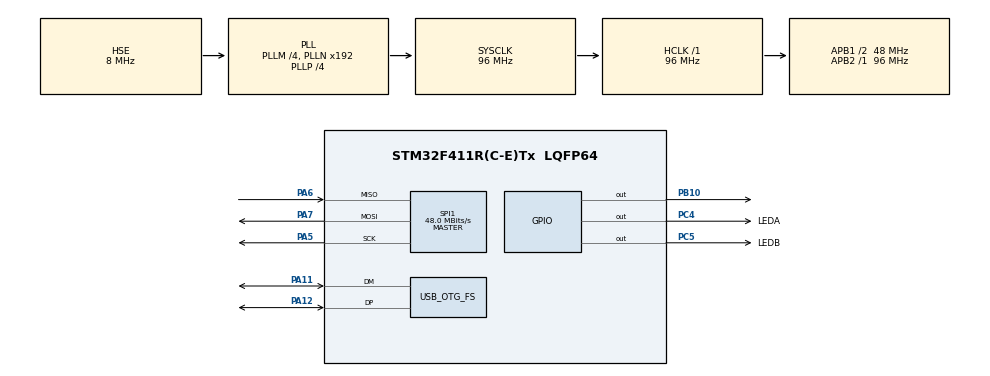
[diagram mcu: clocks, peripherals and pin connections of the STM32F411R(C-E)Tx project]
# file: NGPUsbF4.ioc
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Mcu.Family=STM32F4
Mcu.Name=STM32F411R(C-E)Tx
Mcu.Package=LQFP64
NVIC.OTG_FS_IRQn=true\:0\:0\:false\:false\:true
NVIC.PriorityGroup=NVIC_PRIORITYGROUP_4
PA11.Mode=Device_Only
PA11.Signal=USB_OTG_FS_DM
PA12.Mode=Device_Only
PA12.Signal=USB_OTG_FS_DP
PA5.Mode=Full_Duplex_Master
PA5.Signal=SPI1_SCK
PA6.Mode=Full_Duplex_Master
PA6.Signal=SPI1_MISO
PA7.Mode=Full_Duplex_Master
PA7.Signal=SPI1_MOSI
PB10.GPIO_ModeDefaultOutputPP=GPIO_MODE_OUTPUT_PP
PB10.GPIO_PuPd=GPIO_NOPULL
PB10.GPIO_Speed=GPIO_SPEED_FREQ_LOW
PB10.PinState=GPIO_PIN_RESET
PB10.Signal=GPIO_Output
PC14-OSC32_IN.Mode=LSE-External-Oscillator
PC14-OSC32_IN.Signal=RCC_OSC32_IN
PC15-OSC32_OUT.Mode=LSE-External-Oscillator
PC15-OSC32_OUT.Signal=RCC_OSC32_OUT
PC4.GPIO_Label=LEDA
PC4.GPIO_ModeDefaultOutputPP=GPIO_MODE_OUTPUT_PP
PC4.GPIO_PuPd=GPIO_NOPULL
PC4.GPIO_Speed=GPIO_SPEED_FREQ_LOW
PC4.PinState=GPIO_PIN_RESET
PC4.Signal=GPIO_Output
PC5.GPIO_Label=LEDB
PC5.GPIO_ModeDefaultOutputPP=GPIO_MODE_OUTPUT_PP
PC5.GPIO_PuPd=GPIO_NOPULL
PC5.GPIO_Speed=GPIO_SPEED_FREQ_LOW
PC5.PinState=GPIO_PIN_RESET
PC5.Signal=GPIO_Output
PH0\ -\ OSC_IN.Mode=HSE-External-Oscillator
PH0\ -\ OSC_IN.Signal=RCC_OSC_IN
PH1\ -\ OSC_OUT.Mode=HSE-External-Oscillator
PH1\ -\ OSC_OUT.Signal=RCC_OSC_OUT
ProjectManager.HeapSize=0x200
ProjectManager.StackSize=0x400
ProjectManager.TargetToolchain=MDK-ARM V5
RCC.48MHZClocksFreq_Value=48000000
RCC.AHBFreq_Value=96000000
RCC.APB1CLKDivider=RCC_HCLK_DIV2
RCC.APB1Freq_Value=48000000
RCC.APB1TimFreq_Value=96000000
RCC.APB2Freq_Value=96000000
RCC.APB2TimFreq_Value=96000000
RCC.CortexFreq_Value=96000000
RCC.EnbaleCSS=true
RCC.HCLKFreq_Value=96000000
RCC.HSE_VALUE=8000000
RCC.HSI_VALUE=16000000
RCC.PLLM=4
RCC.PLLP=RCC_PLLP_DIV4
RCC.PLLQ=8
RCC.SYSCLKFreq_VALUE=96000000
RCC.SYSCLKSource=RCC_SYSCLKSOURCE_PLLCLK
RCC.VCOOutputFreq_Value=384000000
SPI1.CalculateBaudRate=48.0 MBits/s
SPI1.Mode=SPI_MODE_MASTER
USB_OTG_FS.VirtualMode=Device_Only
board=NGPUsbF4

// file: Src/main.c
/**
  ******************************************************************************
  * File Name          : main.c
  * Description        : Main program body
  ******************************************************************************
  *
  * COPYRIGHT(c) 2016 STMicroelectronics
  *
  * Redistribution and use in source and binary forms, with or without modification,
  * are permitted provided that the following conditions are met:
  *   1. Redistributions of source code must retain the above copyright notice,
  *      this list of conditions and the following disclaimer.
  *   2. Redistributions in binary form must reproduce the above copyright notice,
  *      this list of conditions and the following disclaimer in the documentation
  *      and/or other materials provided with the distribution.
  *   3. Neither the name of STMicroelectronics nor the names of its contributors
  *      may be used to endorse or promote products derived from this software
  *      without specific prior written permission.
  *
  * THIS SOFTWARE IS PROVIDED BY THE COPYRIGHT HOLDERS AND CONTRIBUTORS "AS IS"
  * AND ANY EXPRESS OR IMPLIED WARRANTIES, INCLUDING, BUT NOT LIMITED TO, THE
  * IMPLIED WARRANTIES OF MERCHANTABILITY AND FITNESS FOR A PARTICULAR PURPOSE ARE
  * DISCLAIMED. IN NO EVENT SHALL THE COPYRIGHT HOLDER OR CONTRIBUTORS BE LIABLE
  * FOR ANY DIRECT, INDIRECT, INCIDENTAL, SPECIAL, EXEMPLARY, OR CONSEQUENTIAL
  * DAMAGES (INCLUDING, BUT NOT LIMITED TO, PROCUREMENT OF SUBSTITUTE GOODS OR
  * SERVICES; LOSS OF USE, DATA, OR PROFITS; OR BUSINESS INTERRUPTION) HOWEVER
  * CAUSED AND ON ANY THEORY OF LIABILITY, WHETHER IN CONTRACT, STRICT LIABILITY,
  * OR TORT (INCLUDING NEGLIGENCE OR OTHERWISE) ARISING IN ANY WAY OUT OF THE USE
  * OF THIS SOFTWARE, EVEN IF ADVISED OF THE POSSIBILITY OF SUCH DAMAGE.
  *
  ******************************************************************************
  */
#include "main.h"
#include "stm32f4xx_hal.h"

SPI_HandleTypeDef hspi1;

PCD_HandleTypeDef hpcd_USB_OTG_FS;

/* USER CODE BEGIN PV */
/* Private variables ---------------------------------------------------------*/

/* USER CODE END PV */

void SystemClock_Config(void);
void Error_Handler(void);
static void MX_GPIO_Init(void);
static void MX_SPI1_Init(void);
static void MX_USB_OTG_FS_PCD_Init(void);

/* USER CODE BEGIN PFP */
/* Private function prototypes -----------------------------------------------*/

/* USER CODE END PFP */

int main(void)
{

  /* MCU Configuration----------------------------------------------------------*/

  /* Reset of all peripherals, Initializes the Flash interface and the Systick. */
  HAL_Init();

  /* Configure the system clock */
  SystemClock_Config();

  /* Initialize all configured peripherals */
  MX_GPIO_Init();
  MX_SPI1_Init();
  MX_USB_OTG_FS_PCD_Init();

  /* USER CODE BEGIN 2 */
	HAL_GPIO_TogglePin(LEDA_GPIO_Port, LEDA_Pin);
  /* USER CODE END 2 */

  /* Infinite loop */
  /* USER CODE BEGIN WHILE */
  while (1)
  {
	  HAL_GPIO_TogglePin(LEDA_GPIO_Port, LEDA_Pin);
	  HAL_GPIO_TogglePin(LEDB_GPIO_Port, LEDB_Pin);
	  HAL_Delay(100);
  /* USER CODE END WHILE */

  }

}

/** System Clock Configuration
*/
void SystemClock_Config(void)
{

  RCC_OscInitTypeDef RCC_OscInitStruct;
  RCC_ClkInitTypeDef RCC_ClkInitStruct;

    /**Configure the main internal regulator output voltage
    */
  __HAL_RCC_PWR_CLK_ENABLE();

  __HAL_PWR_VOLTAGESCALING_CONFIG(PWR_REGULATOR_VOLTAGE_SCALE1);

    /**Initializes the CPU, AHB and APB busses clocks
    */
  RCC_OscInitStruct.OscillatorType = RCC_OSCILLATORTYPE_HSE;
  RCC_OscInitStruct.HSEState = RCC_HSE_ON;
  RCC_OscInitStruct.PLL.PLLState = RCC_PLL_ON;
  RCC_OscInitStruct.PLL.PLLSource = RCC_PLLSOURCE_HSE;
  RCC_OscInitStruct.PLL.PLLM = 4;
  RCC_OscInitStruct.PLL.PLLN = 192;
  RCC_OscInitStruct.PLL.PLLP = RCC_PLLP_DIV4;
  RCC_OscInitStruct.PLL.PLLQ = 8;
  if (HAL_RCC_OscConfig(&RCC_OscInitStruct) != HAL_OK)
  {
    Error_Handler();
  }

    /**Initializes the CPU, AHB and APB busses clocks
    */
  RCC_ClkInitStruct.ClockType = RCC_CLOCKTYPE_HCLK|RCC_CLOCKTYPE_SYSCLK
                              |RCC_CLOCKTYPE_PCLK1|RCC_CLOCKTYPE_PCLK2;
  RCC_ClkInitStruct.SYSCLKSource = RCC_SYSCLKSOURCE_PLLCLK;
  RCC_ClkInitStruct.AHBCLKDivider = RCC_SYSCLK_DIV1;
  RCC_ClkInitStruct.APB1CLKDivider = RCC_HCLK_DIV2;
  RCC_ClkInitStruct.APB2CLKDivider = RCC_HCLK_DIV1;

  if (HAL_RCC_ClockConfig(&RCC_ClkInitStruct, FLASH_LATENCY_3) != HAL_OK)
  {
    Error_Handler();
  }

    /**Enables the Clock Security System
    */
  HAL_RCC_EnableCSS();

    /**Configure the Systick interrupt time
    */
  HAL_SYSTICK_Config(HAL_RCC_GetHCLKFreq()/1000);

    /**Configure the Systick
    */
  HAL_SYSTICK_CLKSourceConfig(SYSTICK_CLKSOURCE_HCLK);

  /* SysTick_IRQn interrupt configuration */
  HAL_NVIC_SetPriority(SysTick_IRQn, 0, 0);
}

/* SPI1 init function */
static void MX_SPI1_Init(void)
{

  hspi1.Instance = SPI1;
  hspi1.Init.Mode = SPI_MODE_MASTER;
  hspi1.Init.Direction = SPI_DIRECTION_2LINES;
  hspi1.Init.DataSize = SPI_DATASIZE_8BIT;
  hspi1.Init.CLKPolarity = SPI_POLARITY_LOW;
  hspi1.Init.CLKPhase = SPI_PHASE_1EDGE;
  hspi1.Init.NSS = SPI_NSS_SOFT;
  hspi1.Init.BaudRatePrescaler = SPI_BAUDRATEPRESCALER_2;
  hspi1.Init.FirstBit = SPI_FIRSTBIT_MSB;
  hspi1.Init.TIMode = SPI_TIMODE_DISABLE;
  hspi1.Init.CRCCalculation = SPI_CRCCALCULATION_DISABLE;
  hspi1.Init.CRCPolynomial = 10;
  if (HAL_SPI_Init(&hspi1) != HAL_OK)
  {
    Error_Handler();
  }

}

/* USB_OTG_FS init function */
static void MX_USB_OTG_FS_PCD_Init(void)
{

  hpcd_USB_OTG_FS.Instance = USB_OTG_FS;
  hpcd_USB_OTG_FS.Init.dev_endpoints = 4;
  hpcd_USB_OTG_FS.Init.speed = PCD_SPEED_FULL;
  hpcd_USB_OTG_FS.Init.dma_enable = DISABLE;
  hpcd_USB_OTG_FS.Init.ep0_mps = DEP0CTL_MPS_64;
  hpcd_USB_OTG_FS.Init.phy_itface = PCD_PHY_EMBEDDED;
  hpcd_USB_OTG_FS.Init.Sof_enable = DISABLE;
  hpcd_USB_OTG_FS.Init.low_power_enable = DISABLE;
  hpcd_USB_OTG_FS.Init.lpm_enable = DISABLE;
  hpcd_USB_OTG_FS.Init.vbus_sensing_enable = ENABLE;
  hpcd_USB_OTG_FS.Init.use_dedicated_ep1 = DISABLE;
  if (HAL_PCD_Init(&hpcd_USB_OTG_FS) != HAL_OK)
  {
    Error_Handler();
  }

}

/** Configure pins as
        * Analog
        * Input
        * Output
        * EVENT_OUT
        * EXTI
*/
static void MX_GPIO_Init(void)
{

  GPIO_InitTypeDef GPIO_InitStruct;

  /* GPIO Ports Clock Enable */
  __HAL_RCC_GPIOC_CLK_ENABLE();
  __HAL_RCC_GPIOH_CLK_ENABLE();
  __HAL_RCC_GPIOA_CLK_ENABLE();
  __HAL_RCC_GPIOB_CLK_ENABLE();

  /*Configure GPIO pin Output Level */
  HAL_GPIO_WritePin(GPIOC, LEDA_Pin|LEDB_Pin, GPIO_PIN_RESET);

  /*Configure GPIO pin Output Level */
  HAL_GPIO_WritePin(GPIOB, GPIO_PIN_10, GPIO_PIN_RESET);

  /*Configure GPIO pins : LEDA_Pin LEDB_Pin */
  GPIO_InitStruct.Pin = LEDA_Pin|LEDB_Pin;
  GPIO_InitStruct.Mode = GPIO_MODE_OUTPUT_PP;
  GPIO_InitStruct.Pull = GPIO_NOPULL;
  GPIO_InitStruct.Speed = GPIO_SPEED_FREQ_LOW;
  HAL_GPIO_Init(GPIOC, &GPIO_InitStruct);

  /*Configure GPIO pin : PB10 */
  GPIO_InitStruct.Pin = GPIO_PIN_10;
  GPIO_InitStruct.Mode = GPIO_MODE_OUTPUT_PP;
  GPIO_InitStruct.Pull = GPIO_NOPULL;
  GPIO_InitStruct.Speed = GPIO_SPEED_FREQ_LOW;
  HAL_GPIO_Init(GPIOB, &GPIO_InitStruct);

}

void Error_Handler(void)
{
  while(1)
  {
  }
}

/************************ (C) COPYRIGHT STMicroelectronics *****END OF FILE****/
